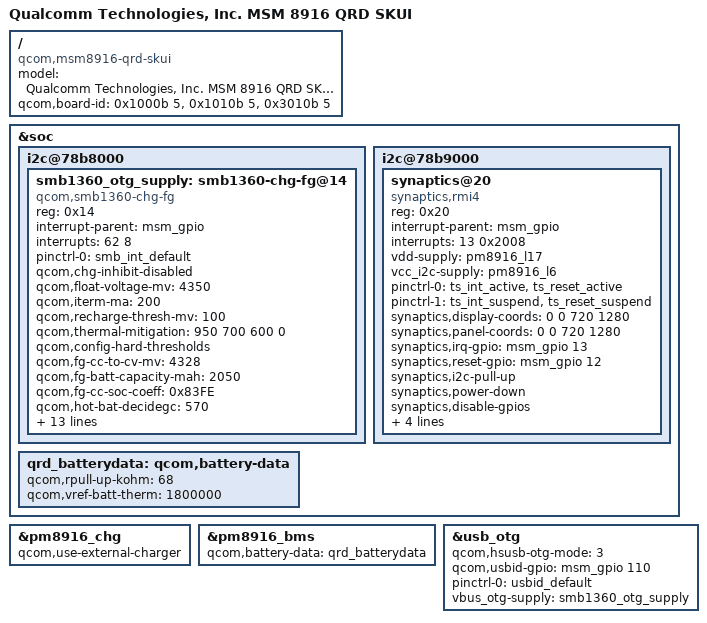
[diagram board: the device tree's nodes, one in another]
/* Copyright (c) 2014, The Linux Foundation. All rights reserved.
 *
 * This program is free software; you can redistribute it and/or modify
 * it under the terms of the GNU General Public License version 2 and
 * only version 2 as published by the Free Software Foundation.
 *
 * This program is distributed in the hope that it will be useful,
 * but WITHOUT ANY WARRANTY; without even the implied warranty of
 * MERCHANTABILITY or FITNESS FOR A PARTICULAR PURPOSE.  See the
 * GNU General Public License for more details.
 */

/dts-v1/;

#include "msm8916-qrd-skui.dtsi"
#include "msm8916-memory.dtsi"

/ {
	model = "Qualcomm Technologies, Inc. MSM 8916 QRD SKUI";
	compatible = "qcom,msm8916-qrd-skui", "qcom,msm8916-qrd", "qcom,msm8916", "qcom,qrd";
	qcom,board-id = <0x1000b 5> , <0x1010b 5> , <0x3010b 5>;
};

&soc {
	i2c@78b8000 {
		smb1360_otg_supply: smb1360-chg-fg@14 {
			compatible = "qcom,smb1360-chg-fg";
			reg = <0x14>;
			interrupt-parent = <&msm_gpio>;
			interrupts = <62 8>;
			pinctrl-names = "default";
			pinctrl-0 = <&smb_int_default>;
			qcom,chg-inhibit-disabled;
			qcom,float-voltage-mv = <4350>;
			qcom,iterm-ma = <200>;
			qcom,recharge-thresh-mv = <100>;
			//add by lishengli 20150406   set limit current to 950
			qcom,thermal-mitigation = <950 700 600 0>;
                        qcom,config-hard-thresholds;
			qcom,fg-cc-to-cv-mv = <4328>;
                        qcom,fg-batt-capacity-mah = <2050>;
                        qcom,fg-cc-soc-coeff = <0x83FE>;
                        qcom,hot-bat-decidegc = <570>;
                        qcom,cold-bat-decidegc = <(0)>;
			qcom,soft-jeita-supported;
			qcom,warm-bat-decidegc = <450>;
			qcom,cool-bat-decidegc = <100>;
			qcom,warm-bat-mv = <4100>;
			qcom,cool-bat-mv = <4100>;
			qcom,warm-bat-ma = <750>;
			qcom,cool-bat-ma = <750>;
			qcom,shdn-after-pwroff = <1>;
			//LINE <otg> <DATA20150420> <otg current> limi.zhang
			qcom,otg-batt-curr-limit = <1500>;
			//add by lishengli 20150210   set cutoff-voltage
			qcom,fg-cutoff-voltage-mv = <3400>;
			qcom,fg-auto-recharge-soc = <99>;
			regulator-name = "smb1360_otg_vreg";
		};
	};

	i2c@78b9000 { /* BLSP1 QUP5 */
		/*focaltech@38 {
			compatible = "focaltech,5x06";
			reg = <0x38>;
			interrupt-parent = <&msm_gpio>;
			interrupts = <13 0x2>;
			vdd-supply = <&pm8916_l17>;
			vcc_i2c-supply = <&pm8916_l6>;
			// pins used by touchscreen 
			pinctrl-names = "pmx_ts_active","pmx_ts_suspend","pmx_ts_release";
			pinctrl-0 = <&ts_int_active &ts_reset_active>;
			pinctrl-1 = <&ts_int_suspend &ts_reset_suspend>;
			pinctrl-2 = <&ts_release>;
			focaltech,name = "ft6436";
			focaltech,family-id = <0x36>;
			focaltech,reset-gpio = <&msm_gpio 12 0x0>;
			focaltech,irq-gpio = <&msm_gpio 13 0x0>;
			focaltech,display-coords = <0 0 480 854>;
			focaltech,panel-coords = <0 0 480 950>;
			focaltech,button-map= <139 102 158>;
			focaltech,no-force-update;
			focaltech,i2c-pull-up;
			focaltech,group-id = <1>;
			focaltech,hard-reset-delay-ms = <20>;
			focaltech,soft-reset-delay-ms = <200>;
			focaltech,num-max-touches = <5>;
			focaltech,fw-delay-aa-ms = <30>;
			focaltech,fw-delay-55-ms = <30>;
			focaltech,fw-upgrade-id1 = <0x79>;
			focaltech,fw-upgrade-id2 = <0x18>;
			focaltech,fw-delay-readid-ms = <10>;
			focaltech,fw-delay-era-flsh-ms = <2000>;
			focaltech,fw-auto-cal;
			focaltech,ignore-id-check;
		};*/

		synaptics@20 {
			compatible = "synaptics,rmi4";
			reg = <0x20>;
			interrupt-parent = <&msm_gpio>;
			interrupts = <13 0x2008>;
                        vdd-supply = <&pm8916_l17>;
                        vcc_i2c-supply = <&pm8916_l6>;
			/* pins used by touchscreen */
			pinctrl-names = "pmx_ts_active","pmx_ts_suspend";
			pinctrl-0 = <&ts_int_active &ts_reset_active>;
			pinctrl-1 = <&ts_int_suspend &ts_reset_suspend>;
			synaptics,display-coords = <0 0 720 1280>;
			synaptics,panel-coords = <0 0 720 1280>;
			synaptics,irq-gpio = <&msm_gpio 13 0x2008>;
			synaptics,reset-gpio = <&msm_gpio 12 0x0>;
			synaptics,i2c-pull-up;
			synaptics,power-down;
			synaptics,disable-gpios;
                        synaptics,power-delay-ms = <160>;
                        synaptics,reset-delay-ms = <100>;
			synaptics,fw-image-name = "PR1797455-s3508r_Tinno_9010.img";
			//synaptics,fw-image-name-jtouch = "PR1624204_s3508_r_9010.img";
			//synaptics,fw-image-name-ttouch = "PR1624204_s3508_r_9010.img";
		};

	};

	/*gen-vkeys {
		compatible = "qcom,gen-vkeys";
		label = "ft5x06_ts";
		qcom,disp-maxx = <480>;
		qcom,disp-maxy = <854>;
		qcom,panel-maxx = <480>;
		qcom,panel-maxy = <946>;
		qcom,key-codes = <139 172 158>;
		qcom,y-offset = <0>;
	};*/

	qrd_batterydata: qcom,battery-data {
		qcom,rpull-up-kohm = <68>;
		qcom,vref-batt-therm = <1800000>;

		#include "batterydata-qrd-4v35-2400mah.dtsi"
	};
};

&pm8916_chg {
	status = "ok";
	qcom,use-external-charger;
};

&pm8916_bms {
	status = "ok";
	qcom,battery-data = <&qrd_batterydata>;
};

&usb_otg {
	qcom,hsusb-otg-mode = <3>;
	qcom,usbid-gpio = <&msm_gpio 110 0>;
	pinctrl-names = "default";
	pinctrl-0 = <&usbid_default>;
	vbus_otg-supply = <&smb1360_otg_supply>;
};
